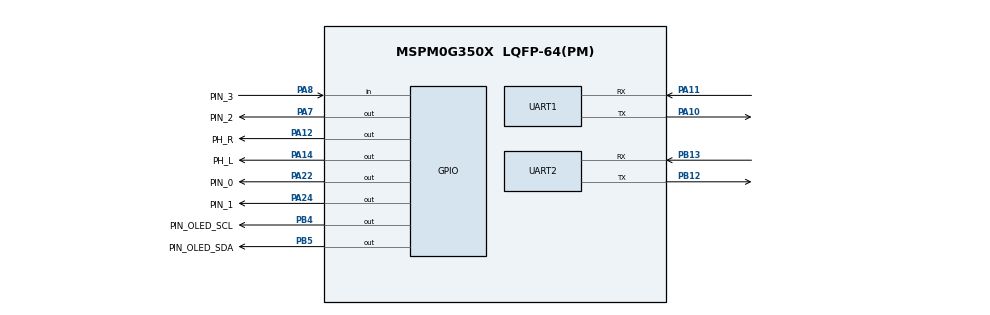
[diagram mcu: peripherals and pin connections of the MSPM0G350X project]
/**
 * @cliArgs --device "MSPM0G350X" --part "Default" --package "LQFP-64(PM)" --product "mspm0_sdk@2.09.00.00"
 * @versions {"tool":"1.25.0+4268"}
 */

/**
 * Import the modules used in this configuration.
 */
const GPIO    = scripting.addModule("/ti/driverlib/GPIO", {}, false);
const GPIO1   = GPIO.addInstance();
const GPIO2   = GPIO.addInstance();
const GPIO3   = GPIO.addInstance();
const GPIO4   = GPIO.addInstance();
const PWM     = scripting.addModule("/ti/driverlib/PWM", {}, false);
const PWM1    = PWM.addInstance();
const SYSCTL  = scripting.addModule("/ti/driverlib/SYSCTL");
const SYSTICK = scripting.addModule("/ti/driverlib/SYSTICK");
const TIMER   = scripting.addModule("/ti/driverlib/TIMER", {}, false);
const TIMER1  = TIMER.addInstance();
const UART    = scripting.addModule("/ti/driverlib/UART", {}, false);
const UART1   = UART.addInstance();
const UART2   = UART.addInstance();

/**
 * Write custom configuration values to the imported modules.
 */
const gate7  = system.clockTree["MFCLKGATE"];
gate7.enable = true;

const multiplier2         = system.clockTree["PLL_QDIV"];
multiplier2.multiplyValue = 5;

const Board = scripting.addModule("/ti/driverlib/Board", {}, false);

GPIO1.$name                          = "DRV8701";
GPIO1.port                           = "PORTA";
GPIO1.associatedPins.create(2);
GPIO1.associatedPins[0].$name        = "PH_L";
GPIO1.associatedPins[0].assignedPin  = "14";
GPIO1.associatedPins[0].pin.$assign  = "PA14";
GPIO1.associatedPins[1].$name        = "PH_R";
GPIO1.associatedPins[1].assignedPin  = "12";
GPIO1.associatedPins[1].pin.$assign  = "PA12";

GPIO2.$name                              = "GPIO_ENCODER";
GPIO2.associatedPins.create(4);
GPIO2.associatedPins[0].$name            = "ENC_L_A";
GPIO2.associatedPins[0].assignedPort     = "PORTB";
GPIO2.associatedPins[0].assignedPin      = "0";
GPIO2.associatedPins[0].direction        = "INPUT";
GPIO2.associatedPins[0].internalResistor = "PULL_UP";
GPIO2.associatedPins[0].interruptEn      = true;
GPIO2.associatedPins[0].polarity         = "RISE_FALL";
GPIO2.associatedPins[1].$name            = "ENC_L_B";
GPIO2.associatedPins[1].assignedPort     = "PORTB";
GPIO2.associatedPins[1].assignedPin      = "1";
GPIO2.associatedPins[1].direction        = "INPUT";
GPIO2.associatedPins[1].internalResistor = "PULL_UP";
GPIO2.associatedPins[1].interruptEn      = true;
GPIO2.associatedPins[1].polarity         = "RISE_FALL";
GPIO2.associatedPins[2].$name            = "ENC_R_A";
GPIO2.associatedPins[2].assignedPort     = "PORTB";
GPIO2.associatedPins[2].assignedPin      = "10";
GPIO2.associatedPins[2].direction        = "INPUT";
GPIO2.associatedPins[2].internalResistor = "PULL_UP";
GPIO2.associatedPins[2].interruptEn      = true;
GPIO2.associatedPins[2].polarity         = "RISE_FALL";
GPIO2.associatedPins[3].$name            = "ENC_R_B";
GPIO2.associatedPins[3].assignedPort     = "PORTB";
GPIO2.associatedPins[3].assignedPin      = "11";
GPIO2.associatedPins[3].direction        = "INPUT";
GPIO2.associatedPins[3].internalResistor = "PULL_UP";
GPIO2.associatedPins[3].interruptEn      = true;
GPIO2.associatedPins[3].polarity         = "RISE_FALL";

GPIO3.$name                         = "GrayS";
GPIO3.port                          = "PORTA";
GPIO3.associatedPins.create(4);
GPIO3.associatedPins[0].$name       = "PIN_0";
GPIO3.associatedPins[0].pin.$assign = "PA22";
GPIO3.associatedPins[1].$name       = "PIN_1";
GPIO3.associatedPins[1].pin.$assign = "PA24";
GPIO3.associatedPins[2].$name       = "PIN_2";
GPIO3.associatedPins[2].pin.$assign = "PA7";
GPIO3.associatedPins[3].$name       = "PIN_3";
GPIO3.associatedPins[3].direction   = "INPUT";
GPIO3.associatedPins[3].pin.$assign = "PA8";

GPIO4.$name                         = "GPIO_OLED";
GPIO4.associatedPins.create(2);
GPIO4.associatedPins[0].$name       = "PIN_OLED_SCL";
GPIO4.associatedPins[0].pin.$assign = "PB4";
GPIO4.associatedPins[1].$name       = "PIN_OLED_SDA";
GPIO4.associatedPins[1].pin.$assign = "PB5";

PWM1.$name               = "PWM_0";
PWM1.clockDivider        = 8;
PWM1.peripheral.$assign  = "TIMA1";
PWM1.PWM_CHANNEL_0.$name = "ti_driverlib_pwm_PWMTimerCC0";
PWM1.PWM_CHANNEL_1.$name = "ti_driverlib_pwm_PWMTimerCC1";
PWM1.ccp0PinConfig.$name = "ti_driverlib_gpio_GPIOPinGeneric_PWM0";
PWM1.ccp1PinConfig.$name = "ti_driverlib_gpio_GPIOPinGeneric_PWM1";

SYSCTL.forceDefaultClkConfig = true;
SYSCTL.clockTreeEn           = true;

SYSTICK.periodEnable  = true;
SYSTICK.systickEnable = true;
SYSTICK.period        = 32;

TIMER1.$name              = "SysTick_Timer";
TIMER1.timerMode          = "PERIODIC";
TIMER1.timerClkPrescale   = 32;
TIMER1.timerPeriod        = "0.001 s";
TIMER1.timerStartTimer    = true;
TIMER1.interrupts         = ["ZERO"];
TIMER1.peripheral.$assign = "TIMG7";

UART1.$name                    = "UART_0";
UART1.enabledInterrupts        = ["RX"];
UART1.targetBaudRate           = 115200;
UART1.peripheral.rxPin.$assign = "PA11";
UART1.peripheral.txPin.$assign = "PA10";
UART1.txPinConfig.$name        = "ti_driverlib_gpio_GPIOPinGeneric0";
UART1.rxPinConfig.$name        = "ti_driverlib_gpio_GPIOPinGeneric1";

/* ---- DMA: UART0 TX -> DMA CH2 (内存->外设) ---- */
UART1.enableDMATX              = true;
UART1.enabledDMATXTriggers     = "DL_UART_DMA_INTERRUPT_TX";
UART1.enableFIFO               = true;
UART1.rxFifoThreshold          = "DL_UART_RX_FIFO_LEVEL_ONE_ENTRY";
UART1.txFifoThreshold          = "DL_UART_TX_FIFO_LEVEL_ONE_ENTRY";
UART1.DMA_CHANNEL_TX.$name     = "DMA_UART0_TX";
UART1.DMA_CHANNEL_TX.addressMode = "b2f";
UART1.DMA_CHANNEL_TX.srcLength = "BYTE";
UART1.DMA_CHANNEL_TX.dstLength = "BYTE";
UART1.DMA_CHANNEL_TX.peripheral.$assign = "DMA_CH2";

/* ---- MSP->STM32 平衡控制链路: UART3, TX=PB12, RX=PB13, 115200 8N1, 阻塞式发送 ---- */
UART2.$name                    = "UART_LINK";
UART2.targetBaudRate           = 115200;
UART2.peripheral.$assign       = "UART3";
UART2.peripheral.txPin.$assign = "PB12";
UART2.peripheral.rxPin.$assign = "PB13";
UART2.txPinConfig.$name        = "ti_driverlib_gpio_GPIOPinGeneric2";
UART2.rxPinConfig.$name        = "ti_driverlib_gpio_GPIOPinGeneric3";

/**
 * Pinmux solution for unlocked pins/peripherals. This ensures that minor changes to the automatic solver in a future
 * version of the tool will not impact the pinmux you originally saw.  These lines can be completely deleted in order to
 * re-solve from scratch.
 */
Board.peripheral.$suggestSolution                = "DEBUGSS";
Board.peripheral.swclkPin.$suggestSolution       = "PA20";
Board.peripheral.swdioPin.$suggestSolution       = "PA19";
GPIO1.associatedPins[0].pin.$suggestSolution     = "PA14";
GPIO1.associatedPins[1].pin.$suggestSolution     = "PA12";
GPIO2.associatedPins[0].pin.$suggestSolution     = "PB0";
GPIO2.associatedPins[1].pin.$suggestSolution     = "PB1";
GPIO2.associatedPins[2].pin.$suggestSolution     = "PB10";
GPIO2.associatedPins[3].pin.$suggestSolution     = "PB11";
PWM1.peripheral.ccp0Pin.$suggestSolution         = "PA17";
PWM1.peripheral.ccp1Pin.$suggestSolution         = "PA16";
UART1.peripheral.$suggestSolution                = "UART0";
UART2.peripheral.$suggestSolution                = "UART3";
